# STM32C071 register map
File version: 1.3
CPU: CM0+ r0p0, little endian, MPU, no FPU, 2 interrupt priority bits
Registers are 32-bit, read-write, reset 0x0 unless marked. A register's access mark holds for its fields unless they carry their own. Offsets are from the block's base; [hi:lo] are bit positions.

## IWDG — IWDG address block description
Base 0x40003000
0x00 KR 16-bit wo — IWDG key register
  [15:0] KEY — Key value (write only, read 0x0000) These bits must be written by software at regular intervals with the key value 0xAAAA, otherwise the watchdog generates a reset when the counter reaches 0. Writing the key value 0x5555 to enable access to the IWDG_PR, IWDG_RLR and IWDG_WINR registers (see Section 22.3.4: Register access protection) Writing the key value 0xCCCC starts the watchdog (except if the hardware watchdog option is selected)
    0x5555=Unlock (Enable access to PR, RLR and WINR registers); 0xAAAA=Feed watchdog with RLR register value; 0xCCCC=Start the watchdog
0x04 PR 16-bit — IWDG prescaler register
  [2:0] PR — Prescaler divider These bits are write access protected see Section 22.3.4: Register access protection. They are written by software to select the prescaler divider feeding the counter clock. PVU bit of the IWDG status register (IWDG_SR) must be reset in order to be able to change the prescaler divider. Note: Reading this register returns the prescaler value from the V<sub>DD</sub> voltage domain. This value may not be up to date/valid if a write operation to this register is ongoing. For this reason the value read from this register is valid only when the PVU bit in the IWDG status register (IWDG_SR) is reset.
    0=DivideBy4 (Divider /4); 1=DivideBy8 (Divider /8); 2=DivideBy16 (Divider /16); 3=DivideBy32 (Divider /32); 4=DivideBy64 (Divider /64); 5=DivideBy128 (Divider /128); other=DivideBy256 (Divider /256)
0x08 RLR 16-bit reset 0xFFF — IWDG reload register
  [11:0] RL — Watchdog counter reload value These bits are write access protected see Register access protection. They are written by software to define the value to be loaded in the watchdog counter each time the value 0xAAAA is written in the IWDG key register (IWDG_KR). The watchdog counter counts down from this value. The timeout period is a function of this value and the clock prescaler. Refer to the datasheet for the timeout information. The RVU bit in the IWDG status register (IWDG_SR) must be reset to be able to change the reload value. Note: Reading this register returns the reload value from the V<sub>DD</sub> voltage domain. This value may not be up to date/valid if a write operation to this register is ongoing on it. For this reason the value read from this register is valid only when the RVU bit in the IWDG status register (IWDG_SR) is reset.
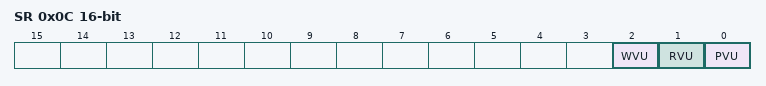
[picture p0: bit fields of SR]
0x0C SR 16-bit ro — IWDG status register
  [2] WVU — Watchdog counter window value update This bit is set by hardware to indicate that an update of the window value is ongoing. It is reset by hardware when the reload value update operation is completed in the V<sub>DD</sub> voltage domain (takes up to five LSI cycles). Window value can be updated only when WVU bit is reset.
  [1] RVU — Watchdog counter reload value update This bit is set by hardware to indicate that an update of the reload value is ongoing. It is reset by hardware when the reload value update operation is completed in the V<sub>DD</sub> voltage domain (takes up to five LSI cycles). Reload value can be updated only when RVU bit is reset.
  [0] PVU — Watchdog prescaler value update This bit is set by hardware to indicate that an update of the prescaler value is ongoing. It is reset by hardware when the prescaler update operation is completed in the V<sub>DD</sub> voltage domain (takes up to five LSI cycles). Prescaler value can be updated only when PVU bit is reset.
0x10 WINR 16-bit reset 0xFFF — IWDG window register
  [11:0] WIN — Watchdog counter window value These bits are write access protected, see Section 22.3.4, they contain the high limit of the window value to be compared with the downcounter. To prevent a reset, the downcounter must be reloaded when its value is lower than the window register value and greater than 0x0 The WVU bit in the IWDG status register (IWDG_SR) must be reset in order to be able to change the reload value. Note: Reading this register returns the reload value from the V<sub>DD</sub> voltage domain. This value may not be valid if a write operation to this register is ongoing. For this reason the value read from this register is valid only when the WVU bit in the IWDG status register (IWDG_SR) is reset.
